# ESP32S31_RADIO register map
Vendor: Espressif; Series: ESP32-S31; File version: 3.52
Registers are 32-bit, read-write, no defined reset value unless marked. A register's access mark holds for its fields unless they carry their own. Offsets are from the block's base; [hi:lo] are bit positions; lines under a group give offsets from that group.

## PHY_FEDATA_RECOVERED — Sparse FEDATA words absent from the public platform PAC.
Base 0x20100400
0x30 WORD_0030_OPAQUE — Opaque: meaning not established. Complete phy_rx_filter_mode performs a read-modify-write of FILTER_MODE; the other fields remain unnamed.
  [21:18] FILTER_MODE — Project-assigned name. Receive filter mode: complete phy_rx_filter_mode replaces these bits with the low four bits of its argument and preserves every other bit.
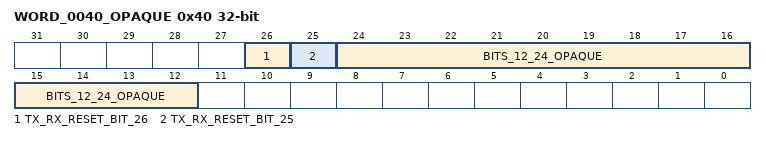
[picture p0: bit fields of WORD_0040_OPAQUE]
0x40 WORD_0040_OPAQUE — Opaque: meaning not established. Complete phy_fe_txrx_reset performs a read-modify-write; individual fields remain unnamed.
  [26] TX_RX_RESET_BIT_26 — Project-assigned name. Second upper reset bit cleared and then asserted by complete phy_fe_txrx_reset.
  [25] TX_RX_RESET_BIT_25 — Project-assigned name. First upper reset bit asserted by complete phy_fe_txrx_reset.
  [24:12] BITS_12_24_OPAQUE — Opaque: meaning not established. Thirteen-bit low reset group cleared by complete phy_fe_txrx_reset.

## PHY_FECTRL_RECOVERED — Sparse FECTRL antenna words absent from the public platform PAC.
Base 0x20100800
0x34 WORD_0034_OPAQUE — Opaque: meaning not established. Read-modify-written by complete antenna configuration functions and saved/restored by complete phy_dig_reg_backup.
0x38 WORD_0038_OPAQUE — Opaque: meaning not established. Read-modify-written by complete antenna configuration functions and saved/restored by complete phy_dig_reg_backup.
0x3C WORD_003C_OPAQUE — Opaque: meaning not established. Read-modify-written by complete antenna configuration functions and saved/restored by complete phy_dig_reg_backup.
0x40 WORD_0040_OPAQUE — Opaque: meaning not established. Read-modify-written by complete antenna configuration functions and saved/restored by complete phy_dig_reg_backup.

## PHY_FEDATA_WIFI_RECOVERED — Sparse FEDATA_WIFI words absent from the public platform PAC.
Base 0x20100C00
0x14 WORD_0014_OPAQUE — Opaque: meaning not established. Complete phy_bb_cfo_cfg reads and replaces this word; individual hardware fields remain unnamed.
0x18 WORD_0018_OPAQUE — Opaque: meaning not established. Complete phy_freq_correct read-modify-writes this word; individual fields remain unnamed.
0x1C WORD_001C_OPAQUE — Opaque: meaning not established. Complete phy_freq_correct read-modify-writes this word; individual fields remain unnamed.

## BLUETOOTH_SCHEDULER_INTERRUPT_RUNTIME — Scheduler words and the MAC diagnostic-signal pair transferred with BLUETOOTH_INTERRUPT_BANK to the primary hard handler. The source-124 reference gate samples scheduler BUSY through the diagnostic pair and can write a complete zero image to SCHEDULER_REFERENCE; the later deferred-work observation reads SCHEDULER_STATE. Task-side scheduler transactions borrow this owner for their own BUSY samples, which serializes every selector write with its value reads. Keeping this sparse physical view outside the task-side controller partition prevents either owner from manufacturing an MMIO alias.
Base 0x20101000
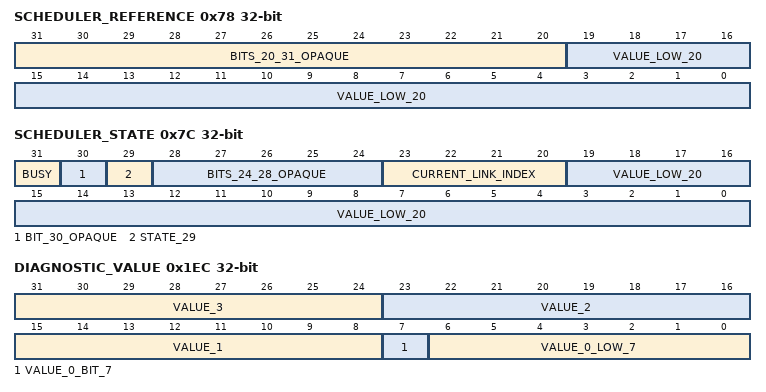
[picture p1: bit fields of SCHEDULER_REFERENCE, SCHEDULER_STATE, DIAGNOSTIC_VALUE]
0x78 SCHEDULER_REFERENCE — Project-assigned name. The source-124 handler can publish the complete zero image when bank-one source 3 observes an idle scheduler through the diagnostic BUSY sample. Other scheduler users compare bits 0..19 or publish complete images; upper encoding remains unknown.
  [31:20] BITS_20_31_OPAQUE — Opaque: meaning not established.
  [19:0] VALUE_LOW_20 — Project-assigned name.
0x7C SCHEDULER_STATE — Project-assigned name. The source-124 handler reads this shared scheduler state before publishing deferred work. Its deferred-work predicate requires both STATE_29 and BUSY. The complete current-link-index leaf returns bits 23:20. Command transactions and the reference gate sample BUSY through DIAGNOSTIC_VALUE instead; other complete users consume or publish the low 20 and low 30 bits.
  [31] BUSY — Project-assigned name.
  [30] BIT_30_OPAQUE — Opaque: meaning not established.
  [29] STATE_29 — Project-assigned name. Positional state sampled together with BUSY by the complete source-124 deferred-work predicate. Its independent hardware meaning remains unqualified.
  [28:24] BITS_24_28_OPAQUE — Opaque: meaning not established.
  [23:20] CURRENT_LINK_INDEX — Project-assigned name. Zero-based current scheduler hardware-list index returned by the complete current-link-index leaf.
  [19:0] VALUE_LOW_20 — Project-assigned name.
0x1E8 DIAGNOSTIC_SELECT wo — Project-assigned name. Bluetooth MAC diagnostic-signal selector. Each byte lane selects one eight-bit diagnostic signal returned in the same lane of DIAGNOSTIC_VALUE. Scheduler command paths and the source-124 reference gate publish the complete SCHEDULER_STATUS image before sampling scheduler BUSY.
  [31:0] SELECTION — Project-assigned name. Complete observed selector images; only the images used by reviewed scheduler transactions are named.
    on write: 56=SCHEDULER_STATUS (Lane zero selects the scheduler status signal; lanes one to three select signal zero.); 0xC01=EXECUTION_MODIFY_PROGRESS (Lane zero selects signal 1 and lane one signal 12. Execution modify repeats its request while lane-zero bits 2:0 hold 2, or hold 3 with lane-one bits 5:4 equal to 1.); 7=EXECUTION_MODIFY_SETTLE (Lane zero selects signal 7; lanes one to three select signal zero. Execution modify completes once the complete value differs from 9.)
0x1EC DIAGNOSTIC_VALUE ro — Project-assigned name. Diagnostic-signal values for the four DIAGNOSTIC_SELECT lanes. The value crosses from the MAC clock domain: readers accept a sample only when two consecutive complete reads are equal.
  [31:24] VALUE_3 — Project-assigned name.
  [23:16] VALUE_2 — Project-assigned name.
  [15:8] VALUE_1 — Project-assigned name.
  [7] VALUE_0_BIT_7 — Project-assigned name. Bit 7 of the lane-zero signal. With SCHEDULER_STATUS selected it is scheduler BUSY, with the polarity of SCHEDULER_STATE.BUSY.
  [6:0] VALUE_0_LOW_7 — Project-assigned name.
